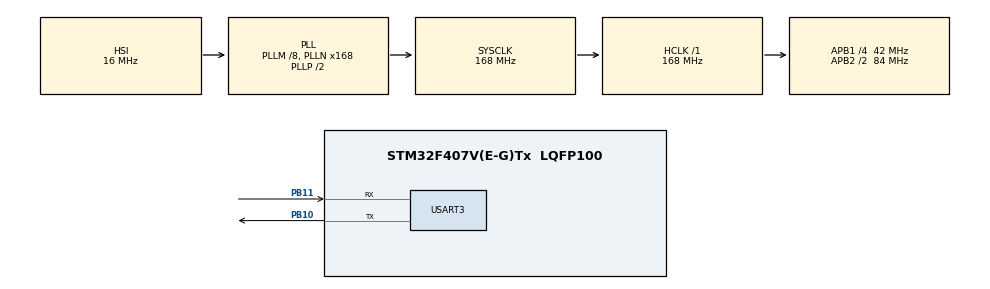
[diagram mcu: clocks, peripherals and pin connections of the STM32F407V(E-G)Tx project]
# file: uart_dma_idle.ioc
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Dma.Request0=USART3_RX
Dma.USART3_RX.0.Direction=DMA_PERIPH_TO_MEMORY
Dma.USART3_RX.0.FIFOMode=DMA_FIFOMODE_DISABLE
Dma.USART3_RX.0.Instance=DMA1_Stream1
Dma.USART3_RX.0.MemDataAlignment=DMA_MDATAALIGN_BYTE
Dma.USART3_RX.0.MemInc=DMA_MINC_ENABLE
Dma.USART3_RX.0.Mode=DMA_NORMAL
Dma.USART3_RX.0.PeriphDataAlignment=DMA_PDATAALIGN_BYTE
Dma.USART3_RX.0.PeriphInc=DMA_PINC_DISABLE
Dma.USART3_RX.0.Priority=DMA_PRIORITY_LOW
Mcu.Family=STM32F4
Mcu.Name=STM32F407V(E-G)Tx
Mcu.Package=LQFP100
NVIC.DMA1_Stream1_IRQn=true\:0\:0\:false\:false\:true\:false\:true
NVIC.PriorityGroup=NVIC_PRIORITYGROUP_0
NVIC.USART3_IRQn=true\:0\:0\:false\:false\:true\:true\:true
PA13.Mode=Serial_Wire
PA13.Signal=SYS_JTMS-SWDIO
PA14.Mode=Serial_Wire
PA14.Signal=SYS_JTCK-SWCLK
PB10.Mode=Asynchronous
PB10.Signal=USART3_TX
PB11.Mode=Asynchronous
PB11.Signal=USART3_RX
PH0-OSC_IN.Mode=HSE-External-Oscillator
PH0-OSC_IN.Signal=RCC_OSC_IN
PH1-OSC_OUT.Mode=HSE-External-Oscillator
PH1-OSC_OUT.Signal=RCC_OSC_OUT
ProjectManager.HeapSize=0x200
ProjectManager.StackSize=0x400
ProjectManager.TargetToolchain=EWARM V8.32
RCC.48MHZClocksFreq_Value=48000000
RCC.AHBFreq_Value=168000000
RCC.APB1CLKDivider=RCC_HCLK_DIV4
RCC.APB1Freq_Value=42000000
RCC.APB1TimFreq_Value=84000000
RCC.APB2CLKDivider=RCC_HCLK_DIV2
RCC.APB2Freq_Value=84000000
RCC.APB2TimFreq_Value=168000000
RCC.CortexFreq_Value=168000000
RCC.HCLKFreq_Value=168000000
RCC.HSE_VALUE=8000000
RCC.HSI_VALUE=16000000
RCC.LSE_VALUE=32768
RCC.PLLM=8
RCC.PLLN=168
RCC.PLLQ=7
RCC.SYSCLKFreq_VALUE=168000000
RCC.SYSCLKSource=RCC_SYSCLKSOURCE_PLLCLK
RCC.VCOOutputFreq_Value=336000000
USART3.VirtualMode=VM_ASYNC
board=STM32F407G-DISC1

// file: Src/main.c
/* USER CODE BEGIN Header */
/**
  ******************************************************************************
  * @file           : main.c
  * @brief          : Main program body
  ******************************************************************************
  * @attention
  *
  * <h2><center>&copy; Copyright (c) 2020 STMicroelectronics.
  * All rights reserved.</center></h2>
  *
  * This software component is licensed by ST under BSD 3-Clause license,
  * the "License"; You may not use this file except in compliance with the
  * License. You may obtain a copy of the License at:
  *                        opensource.org/licenses/BSD-3-Clause
  *
  ******************************************************************************
  */
/* USER CODE END Header */

#include "main.h"

/* USER CODE BEGIN Includes */
#include "DMA_CIRCULAR.h"
#include "string.h"
/* USER CODE END Includes */

UART_HandleTypeDef huart3;
DMA_HandleTypeDef hdma_usart3_rx;

/* USER CODE BEGIN PV */
#define DMA_RX_BUFFER_SIZE          64
uint8_t DMA_RX_Buffer[DMA_RX_BUFFER_SIZE];

#define UART_BUFFER_SIZE            256
uint8_t UART_Buffer[UART_BUFFER_SIZE];

char dma_buffer[64];
/* USER CODE END PV */

void SystemClock_Config(void);
static void MX_GPIO_Init(void);
static void MX_DMA_Init(void);
static void MX_USART3_UART_Init(void);
/* USER CODE BEGIN PFP */
extern void reception_complete_CallBack(void);
/* USER CODE END PFP */

/* USER CODE BEGIN 0 */
#if 0
uint16_t number;
void esp_at (void)
{
	char *string = "AT\r\n";
	HAL_UART_Transmit (&huart3, (uint8_t *)string, 4, 200);
}

void esp_gmr (void)
{
	char *string = "AT+GMR\r\n";
	HAL_UART_Transmit (&huart3, (uint8_t *)string, 8, 200);
}

void waitfor (char *string)
{
	for (int i=0; i<UART_BUFFER_SIZE; i++)
	{
		if ((UART_Buffer[i] == *string));
		}
	}

void clear_buffer(void)
{
	for (int i=0; i<UART_BUFFER_SIZE; i++)
	{
		UART_Buffer [i] = 0;
	}
}

uint16_t esp_waitfor (char *string)
{
  uint8_t so_far = 0;
  char received;
  uint16_t counter = 0;
  for (int i=0; i<UART_BUFFER_SIZE; i++)
	{
				if (UART_Buffer[i] == string[so_far])
				{
					counter=i;
					so_far++;
				}
				else
					so_far = 0;
	}

	return counter;
}

#endif
/* USER CODE END 0 */

int main(void)
{

  /* MCU Configuration--------------------------------------------------------*/

  /* Reset of all peripherals, Initializes the Flash interface and the Systick. */
  HAL_Init();

  /* Configure the system clock */
  SystemClock_Config();

  /* Initialize all configured peripherals */
  MX_GPIO_Init();
  MX_DMA_Init();
  MX_USART3_UART_Init();
  /* USER CODE BEGIN 2 */
    __HAL_UART_ENABLE_IT(&huart3, UART_IT_IDLE);   // enable idle line interrupt
    __HAL_DMA_ENABLE_IT (&hdma_usart3_rx, DMA_IT_TC);  // enable DMA Tx cplt interrupt

    hdma_usart3_rx.Instance->CR &= ~DMA_SxCR_HTIE;

    HAL_UART_Receive_DMA (&huart3, DMA_RX_Buffer, 64);
#if 0

 			esp_at ();
			HAL_Delay (2000);
			clear_buffer ();
			esp_gmr();

		while (HAL_DMA_GetState (&hdma_usart3_rx) == HAL_DMA_STATE_READY);
			number = esp_waitfor ("ok");
#endif
  /* USER CODE END 2 */

  /* Infinite loop */
  while (1)
  {

  }
}

void SystemClock_Config(void)
{
  RCC_OscInitTypeDef RCC_OscInitStruct = {0};
  RCC_ClkInitTypeDef RCC_ClkInitStruct = {0};

  /** Configure the main internal regulator output voltage
  */
  __HAL_RCC_PWR_CLK_ENABLE();
  __HAL_PWR_VOLTAGESCALING_CONFIG(PWR_REGULATOR_VOLTAGE_SCALE1);
  /** Initializes the CPU, AHB and APB busses clocks
  */
  RCC_OscInitStruct.OscillatorType = RCC_OSCILLATORTYPE_HSI;
  RCC_OscInitStruct.HSIState = RCC_HSI_ON;
  RCC_OscInitStruct.HSICalibrationValue = RCC_HSICALIBRATION_DEFAULT;
  RCC_OscInitStruct.PLL.PLLState = RCC_PLL_ON;
  RCC_OscInitStruct.PLL.PLLSource = RCC_PLLSOURCE_HSI;
  RCC_OscInitStruct.PLL.PLLM = 8;
  RCC_OscInitStruct.PLL.PLLN = 168;
  RCC_OscInitStruct.PLL.PLLP = RCC_PLLP_DIV2;
  RCC_OscInitStruct.PLL.PLLQ = 7;
  if (HAL_RCC_OscConfig(&RCC_OscInitStruct) != HAL_OK)
  {
    Error_Handler();
  }
  /** Initializes the CPU, AHB and APB busses clocks
  */
  RCC_ClkInitStruct.ClockType = RCC_CLOCKTYPE_HCLK|RCC_CLOCKTYPE_SYSCLK
                              |RCC_CLOCKTYPE_PCLK1|RCC_CLOCKTYPE_PCLK2;
  RCC_ClkInitStruct.SYSCLKSource = RCC_SYSCLKSOURCE_PLLCLK;
  RCC_ClkInitStruct.AHBCLKDivider = RCC_SYSCLK_DIV1;
  RCC_ClkInitStruct.APB1CLKDivider = RCC_HCLK_DIV4;
  RCC_ClkInitStruct.APB2CLKDivider = RCC_HCLK_DIV2;

  if (HAL_RCC_ClockConfig(&RCC_ClkInitStruct, FLASH_LATENCY_5) != HAL_OK)
  {
    Error_Handler();
  }
}

static void MX_USART3_UART_Init(void)
{

  huart3.Instance = USART3;
  huart3.Init.BaudRate = 115200;
  huart3.Init.WordLength = UART_WORDLENGTH_8B;
  huart3.Init.StopBits = UART_STOPBITS_1;
  huart3.Init.Parity = UART_PARITY_NONE;
  huart3.Init.Mode = UART_MODE_TX_RX;
  huart3.Init.HwFlowCtl = UART_HWCONTROL_NONE;
  huart3.Init.OverSampling = UART_OVERSAMPLING_16;
  if (HAL_UART_Init(&huart3) != HAL_OK)
  {
    Error_Handler();
  }

}

static void MX_DMA_Init(void)
{

  /* DMA controller clock enable */
  __HAL_RCC_DMA1_CLK_ENABLE();

  /* DMA interrupt init */
  /* DMA1_Stream1_IRQn interrupt configuration */
  HAL_NVIC_SetPriority(DMA1_Stream1_IRQn, 0, 0);
  HAL_NVIC_EnableIRQ(DMA1_Stream1_IRQn);

}

static void MX_GPIO_Init(void)
{

  /* GPIO Ports Clock Enable */
  GPIO_InitTypeDef PinConfig;
  __HAL_RCC_GPIOH_CLK_ENABLE();
  __HAL_RCC_GPIOB_CLK_ENABLE();
  __HAL_RCC_GPIOA_CLK_ENABLE();
  __HAL_RCC_GPIOD_CLK_ENABLE();

    PinConfig.Pin       = GPIO_PIN_15;
    PinConfig.Mode      = GPIO_MODE_OUTPUT_PP;
    HAL_GPIO_Init(GPIOD,&PinConfig);

}

/* USER CODE BEGIN 4 */
void reception_complete_CallBack(void)
{

  for(uint8_t i=0; i<64; i++)
  {
    dma_buffer[i] = DMA_RX_Buffer[i];
  }
  if(strcmp(dma_buffer,"unlock") == 0)
   {

        HAL_GPIO_WritePin(GPIOD,GPIO_PIN_15,GPIO_PIN_SET);
      for(uint32_t i=0; i<65535; i++);
       // HAL_Delay(500);

       HAL_GPIO_WritePin(GPIOD,GPIO_PIN_15,GPIO_PIN_RESET);

//        for(uint8_t i=0; i<7; i++)
//        {
//            rx_buffer[i] = 0;
//        }
         // memset(rx_buffer, 0, sizeof(rx_buffer));
    }
    //HAL_UART_Receive_DMA(&huart3, rx_buffer, 7);
    //memset(rx_buffer, 0, sizeof(rx_buffer));
//    for(uint8_t i=0; i<7; i++)
//    {
//      rx_buffer[i] = 0;
//    }
  memset(dma_buffer, 0, sizeof(dma_buffer));
}
/* USER CODE END 4 */

void Error_Handler(void)
{
}

/************************ (C) COPYRIGHT STMicroelectronics *****END OF FILE****/
